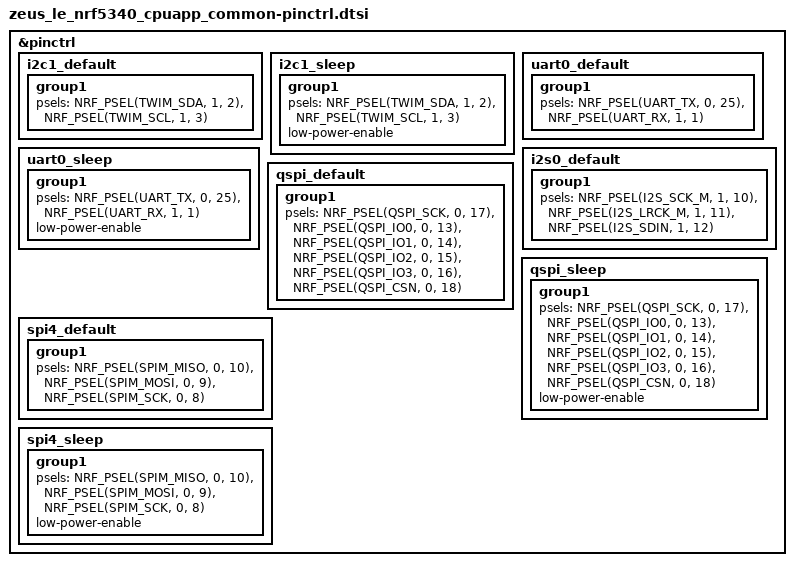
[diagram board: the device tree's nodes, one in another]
/*
 * Copyright (c) 2024 Ben Wolsieffer
 *
 * SPDX-License-Identifier: Apache-2.0
 */

&pinctrl {
	i2c1_default: i2c1_default {
		group1 {
			psels = <NRF_PSEL(TWIM_SDA, 1, 2)>,
				<NRF_PSEL(TWIM_SCL, 1, 3)>;
		};
	};

	i2c1_sleep: i2c1_sleep {
		group1 {
			psels = <NRF_PSEL(TWIM_SDA, 1, 2)>,
				<NRF_PSEL(TWIM_SCL, 1, 3)>;
			low-power-enable;
		};
	};

	uart0_default: uart0_default {
		group1 {
			psels = <NRF_PSEL(UART_TX, 0, 25)>,
				<NRF_PSEL(UART_RX, 1, 1)>;
		};
	};

	uart0_sleep: uart0_sleep {
		group1 {
			psels = <NRF_PSEL(UART_TX, 0, 25)>,
				<NRF_PSEL(UART_RX, 1, 1)>;
			low-power-enable;
		};
	};

	i2s0_default: i2s0_default {
		group1 {
			psels = <NRF_PSEL(I2S_SCK_M, 1, 10)>,
				<NRF_PSEL(I2S_LRCK_M, 1, 11)>,
				<NRF_PSEL(I2S_SDIN, 1, 12)>;
		};
	};

	qspi_default: qspi_default {
		group1 {
			psels = <NRF_PSEL(QSPI_SCK, 0, 17)>,
				<NRF_PSEL(QSPI_IO0, 0, 13)>,
				<NRF_PSEL(QSPI_IO1, 0, 14)>,
				<NRF_PSEL(QSPI_IO2, 0, 15)>,
				<NRF_PSEL(QSPI_IO3, 0, 16)>,
				<NRF_PSEL(QSPI_CSN, 0, 18)>;
		};
	};

	qspi_sleep: qspi_sleep {
		group1 {
			psels = <NRF_PSEL(QSPI_SCK, 0, 17)>,
				<NRF_PSEL(QSPI_IO0, 0, 13)>,
				<NRF_PSEL(QSPI_IO1, 0, 14)>,
				<NRF_PSEL(QSPI_IO2, 0, 15)>,
				<NRF_PSEL(QSPI_IO3, 0, 16)>,
				<NRF_PSEL(QSPI_CSN, 0, 18)>;
			low-power-enable;
		};
	};

	spi4_default: spi4_default {
		group1 {
			psels = <NRF_PSEL(SPIM_MISO, 0, 10)>,
				<NRF_PSEL(SPIM_MOSI, 0, 9)>,
				<NRF_PSEL(SPIM_SCK, 0, 8)>;
		};
	};

	spi4_sleep: spi4_sleep {
		group1 {
			psels = <NRF_PSEL(SPIM_MISO, 0, 10)>,
				<NRF_PSEL(SPIM_MOSI, 0, 9)>,
				<NRF_PSEL(SPIM_SCK, 0, 8)>;
			low-power-enable;
		};
	};
};
